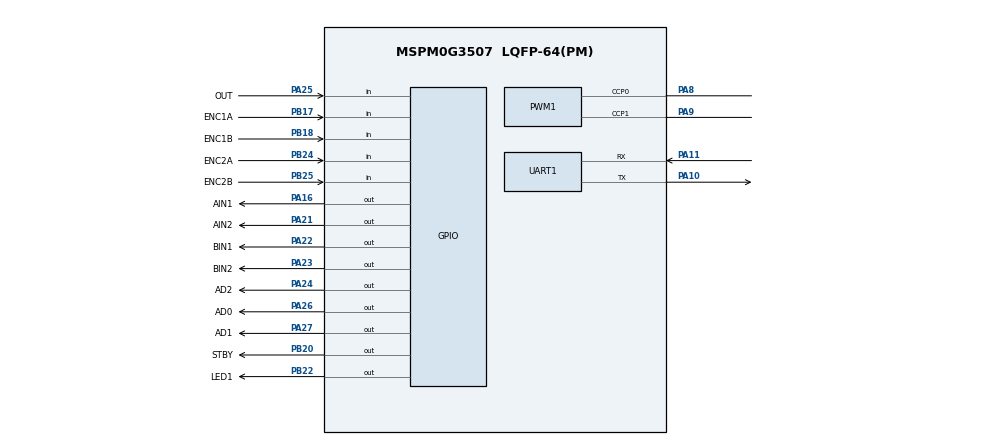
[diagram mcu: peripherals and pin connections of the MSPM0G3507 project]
/**
 * ER2024 firmware bringup for the JLC Tianmengxing MSPM0G3507 board.
 * Step 5: Motor (TB6612) + Encoder bringup.
 *
 * Peripherals:
 * - LED1: PB22, active high
 * - UART0: TX PA10, RX PA11, onboard CH340E USB-to-serial
 * - Line sensor mux: AD0 PA26, AD1 PA27, AD2 PA24, OUT PA25
 * - Motor PWM:  TIMA0 CCP0 PA8 (LEFT), CCP1 PA9 (RIGHT)
 *   Note: PA2/PA14 not accepted by SysConfig 1.28 PWM module.
 *         Hardware must wire PWM_LEFT→PA8, PWM_RIGHT→PA9.
 * - Motor direction: AIN1 PA16, AIN2 PA21, BIN1 PA22, BIN2 PA23
 * - Motor STBY: PB20 (active high)
 * - Encoder L: A PB17 (interrupt), B PB18 (input only)
 * - Encoder R: A PB24 (interrupt), B PB25 (input only)
 * - MPU6050 test software I2C: SCL PB2, SDA PB3
 */
//@cliArgs --device "MSPM0G350X" --package "LQFP-64(PM)" --part "Default"
//@v2CliArgs --device "MSPM0G3507" --package "LQFP-64(PM)"

const GPIO   = scripting.addModule("/ti/driverlib/GPIO", {}, false);
const GPIO1  = GPIO.addInstance();
const GPIO2  = GPIO.addInstance();
const GPIO3  = GPIO.addInstance();
const GPIO4  = GPIO.addInstance();
const GPIO5  = GPIO.addInstance();
const GPIO6  = GPIO.addInstance();
const PWM    = scripting.addModule("/ti/driverlib/PWM", {}, false);
const PWM1   = PWM.addInstance();
const UART   = scripting.addModule("/ti/driverlib/UART", {}, false);
const UART1  = UART.addInstance();
const SYSCTL = scripting.addModule("/ti/driverlib/SYSCTL");

const gate7  = system.clockTree["MFCLKGATE"];
gate7.enable = true;

// ===== GPIO: LED (PB22) =====
GPIO1.$name                              = "GPIO_LED";
GPIO1.port                               = "PORTB";
GPIO1.associatedPins[0].$name            = "LED1";
GPIO1.associatedPins[0].direction        = "OUTPUT";
GPIO1.associatedPins[0].initialValue     = "CLEARED";
GPIO1.associatedPins[0].internalResistor = "PULL_DOWN";
GPIO1.associatedPins[0].assignedPin      = "22";
GPIO1.associatedPins[0].pin.$assign      = "PB22";

// ===== GPIO: Line Sensor Mux Address (PA26, PA27, PA24) =====
GPIO2.$name                              = "GPIO_LINE_ADDR";
GPIO2.port                               = "PORTA";
GPIO2.associatedPins.create(3);
GPIO2.associatedPins[0].$name            = "AD0";
GPIO2.associatedPins[0].direction        = "OUTPUT";
GPIO2.associatedPins[0].initialValue     = "CLEARED";
GPIO2.associatedPins[0].internalResistor = "PULL_DOWN";
GPIO2.associatedPins[0].assignedPin      = "26";
GPIO2.associatedPins[0].pin.$assign      = "PA26";
GPIO2.associatedPins[1].$name            = "AD1";
GPIO2.associatedPins[1].direction        = "OUTPUT";
GPIO2.associatedPins[1].initialValue     = "CLEARED";
GPIO2.associatedPins[1].internalResistor = "PULL_DOWN";
GPIO2.associatedPins[1].assignedPin      = "27";
GPIO2.associatedPins[1].pin.$assign      = "PA27";
GPIO2.associatedPins[2].$name            = "AD2";
GPIO2.associatedPins[2].direction        = "OUTPUT";
GPIO2.associatedPins[2].initialValue     = "CLEARED";
GPIO2.associatedPins[2].internalResistor = "PULL_DOWN";
GPIO2.associatedPins[2].assignedPin      = "24";
GPIO2.associatedPins[2].pin.$assign      = "PA24";

// ===== GPIO: Line Sensor OUT (PA25, input) =====
GPIO3.$name                              = "GPIO_LINE_OUT";
GPIO3.port                               = "PORTA";
GPIO3.associatedPins[0].$name            = "OUT";
GPIO3.associatedPins[0].direction        = "INPUT";
GPIO3.associatedPins[0].internalResistor = "NONE";
GPIO3.associatedPins[0].assignedPin      = "25";
GPIO3.associatedPins[0].pin.$assign      = "PA25";

// ===== GPIO: Motor Direction (PA16 AIN1, PA21 AIN2, PA22 BIN1, PA23 BIN2) =====
GPIO4.$name                              = "GPIO_MOTOR_DIR";
GPIO4.port                               = "PORTA";
GPIO4.associatedPins.create(4);
GPIO4.associatedPins[0].$name            = "AIN1";
GPIO4.associatedPins[0].direction        = "OUTPUT";
GPIO4.associatedPins[0].initialValue     = "CLEARED";
GPIO4.associatedPins[0].internalResistor = "PULL_DOWN";
GPIO4.associatedPins[0].assignedPin      = "16";
GPIO4.associatedPins[0].pin.$assign      = "PA16";
GPIO4.associatedPins[1].$name            = "AIN2";
GPIO4.associatedPins[1].direction        = "OUTPUT";
GPIO4.associatedPins[1].initialValue     = "CLEARED";
GPIO4.associatedPins[1].internalResistor = "PULL_DOWN";
GPIO4.associatedPins[1].assignedPin      = "21";
GPIO4.associatedPins[1].pin.$assign      = "PA21";
GPIO4.associatedPins[2].$name            = "BIN1";
GPIO4.associatedPins[2].direction        = "OUTPUT";
GPIO4.associatedPins[2].initialValue     = "CLEARED";
GPIO4.associatedPins[2].internalResistor = "PULL_DOWN";
GPIO4.associatedPins[2].assignedPin      = "22";
GPIO4.associatedPins[2].pin.$assign      = "PA22";
GPIO4.associatedPins[3].$name            = "BIN2";
GPIO4.associatedPins[3].direction        = "OUTPUT";
GPIO4.associatedPins[3].initialValue     = "CLEARED";
GPIO4.associatedPins[3].internalResistor = "PULL_DOWN";
GPIO4.associatedPins[3].assignedPin      = "23";
GPIO4.associatedPins[3].pin.$assign      = "PA23";

// ===== GPIO: Motor STBY (PB20, active high enable) =====
GPIO5.$name                              = "GPIO_MOTOR_STBY";
GPIO5.port                               = "PORTB";
GPIO5.associatedPins[0].$name            = "STBY";
GPIO5.associatedPins[0].direction        = "OUTPUT";
GPIO5.associatedPins[0].initialValue     = "SET";
GPIO5.associatedPins[0].internalResistor = "PULL_DOWN";
GPIO5.associatedPins[0].assignedPin      = "20";
GPIO5.associatedPins[0].pin.$assign      = "PB20";

// ===== GPIO: Encoder (PB17=ENC1A, PB18=ENC1B, PB24=ENC2A, PB25=ENC2B) =====
GPIO6.$name                              = "GPIO_ENCODER";
GPIO6.port                               = "PORTB";
GPIO6.associatedPins.create(4);
// ENC1A: PB17, interrupt on rising edge
GPIO6.associatedPins[0].$name            = "ENC1A";
GPIO6.associatedPins[0].direction        = "INPUT";
GPIO6.associatedPins[0].internalResistor = "PULL_UP";
GPIO6.associatedPins[0].interruptEn      = true;
GPIO6.associatedPins[0].polarity         = "RISE";
GPIO6.associatedPins[0].interruptPriority = "1";
GPIO6.associatedPins[0].assignedPin      = "17";
GPIO6.associatedPins[0].pin.$assign      = "PB17";
// ENC1B: PB18, input only (no interrupt)
GPIO6.associatedPins[1].$name            = "ENC1B";
GPIO6.associatedPins[1].direction        = "INPUT";
GPIO6.associatedPins[1].internalResistor = "PULL_UP";
GPIO6.associatedPins[1].assignedPin      = "18";
GPIO6.associatedPins[1].pin.$assign      = "PB18";
// ENC2A: PB24, interrupt on rising edge
GPIO6.associatedPins[2].$name            = "ENC2A";
GPIO6.associatedPins[2].direction        = "INPUT";
GPIO6.associatedPins[2].internalResistor = "PULL_UP";
GPIO6.associatedPins[2].interruptEn      = true;
GPIO6.associatedPins[2].polarity         = "RISE";
GPIO6.associatedPins[2].interruptPriority = "1";
GPIO6.associatedPins[2].assignedPin      = "24";
GPIO6.associatedPins[2].pin.$assign      = "PB24";
// ENC2B: PB25, input only (no interrupt)
GPIO6.associatedPins[3].$name            = "ENC2B";
GPIO6.associatedPins[3].direction        = "INPUT";
GPIO6.associatedPins[3].internalResistor = "PULL_UP";
GPIO6.associatedPins[3].assignedPin      = "25";
GPIO6.associatedPins[3].pin.$assign      = "PB25";

// ===== PWM: Motors (TIMA0, CCP0=PA8 LEFT, CCP1=PA9 RIGHT) =====
PWM1.$name                                     = "PWM_MOTORS";
PWM1.clockDivider                              = 8;
PWM1.ccIndex                                   = [0, 1];
PWM1.timerCount                                = 1000;
PWM1.PWM_CHANNEL_0.$name                       = "ti_driverlib_pwm_PWMTimerCC0";
PWM1.PWM_CHANNEL_1.$name                       = "ti_driverlib_pwm_PWMTimerCC1";
PWM1.ccp0PinConfig.direction                   = scripting.forceWrite("OUTPUT");
PWM1.ccp0PinConfig.hideOutputInversion         = scripting.forceWrite(false);
PWM1.ccp0PinConfig.onlyInternalResistor        = scripting.forceWrite(false);
PWM1.ccp0PinConfig.passedPeripheralType        = scripting.forceWrite("Digital");
PWM1.ccp0PinConfig.$name                       = "ti_driverlib_gpio_GPIOPinGeneric10";
PWM1.ccp1PinConfig.direction                   = scripting.forceWrite("OUTPUT");
PWM1.ccp1PinConfig.hideOutputInversion         = scripting.forceWrite(false);
PWM1.ccp1PinConfig.onlyInternalResistor        = scripting.forceWrite(false);
PWM1.ccp1PinConfig.passedPeripheralType        = scripting.forceWrite("Digital");
PWM1.ccp1PinConfig.$name                       = "ti_driverlib_gpio_GPIOPinGeneric11";
PWM1.peripheral.$assign                        = "TIMA0";
PWM1.peripheral.ccp0Pin.$assign                = "PA8";
PWM1.peripheral.ccp1Pin.$assign                = "PA9";

// ===== UART0 (PA10 TX, PA11 RX, 9600-8N1) =====
UART1.$name                    = "UART_0";
UART1.peripheral.$assign       = "UART0";
UART1.peripheral.txPin.$assign = "PA10";
UART1.peripheral.rxPin.$assign = "PA11";
UART1.uartClkSrc               = "MFCLK";
UART1.uartClkDiv               = "1";
UART1.targetBaudRate           = 9600;
UART1.wordLength               = "8_BITS";
UART1.parity                   = "NONE";
UART1.stopBits                 = "ONE";
UART1.flowControl              = "NONE";
UART1.direction                = "TX_RX";
UART1.enableInternalLoopback   = false;
UART1.enableFIFO               = false;
UART1.enabledInterrupts        = ["RX"];
UART1.ovsRate                  = "16";

// ===== SYSCTL =====
SYSCTL.SYSOSC_Freq           = 4000000;
SYSCTL.MFCLKEn               = true;
SYSCTL.forceDefaultClkConfig = true;
SYSCTL.clockTreeEn           = true;
